# M4L2 register map
File version: 0.1
Registers are 32-bit, read-write, reset 0x0 unless marked. A register's access mark holds for its fields unless they carry their own. Offsets are from the block's base; [hi:lo] are bit positions; {n}, {i} and the like mark numbered series.

## PH — Port H
Base 0x40080700
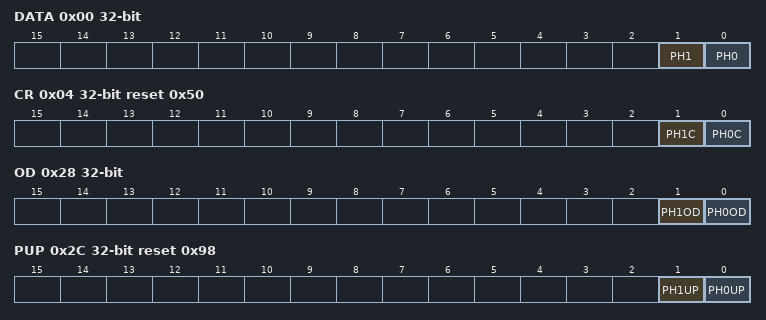
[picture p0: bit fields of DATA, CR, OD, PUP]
0x00 DATA — Port H Data Register
  [1] PH1, [0] PH0
0x04 CR reset 0x50 — Port H Output Control Register
  [1] PH1C, [0] PH0C
0x28 OD — Port H Open Drain Control Register
  [1] PH1OD, [0] PH0OD
0x2C PUP reset 0x98 — Port H Pull-up Control Register
  [1] PH1UP, [0] PH0UP
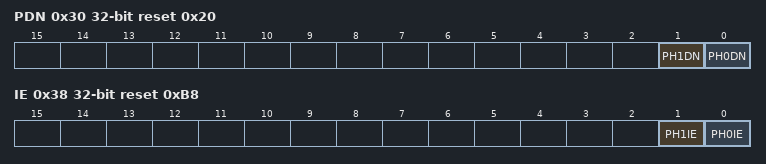
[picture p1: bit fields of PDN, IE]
0x30 PDN reset 0x20 — Port H Pull-down Control Register
  [1] PH1DN, [0] PH0DN
0x38 IE reset 0xB8 — Port H Input Control Register
  [1] PH1IE, [0] PH0IE

## PJ — Port J
Base 0x40080800
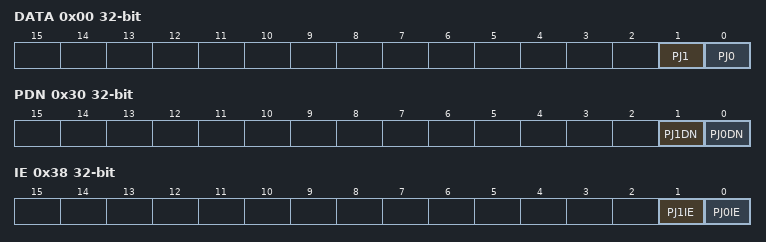
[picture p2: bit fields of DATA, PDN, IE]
0x00 DATA — Port J Data Register
  [1] PJ1, [0] PJ0
0x30 PDN — Port J Pull-down Control Register
  [1] PJ1DN, [0] PJ0DN
0x38 IE — Port J Input Control Register
  [1] PJ1IE, [0] PJ0IE

## PK — Port K
Base 0x40080900
0x00 DATA — Port K Data Register
  [0] PK0
0x04 CR — Port K Output Control Register
  [0] PK0C
0x28 OD — Port K Open Drain Control Register
  [0] PK0OD
0x2C PUP — Port K Pull-up Control Register
  [0] PK0UP
0x30 PDN reset 0x8 — Port K Pull-up Control Register
  [0] PK0DN
0x38 IE — Port K Input Control Register
  [0] PK0IE

## TRM — Internal High-speed Oscillation Adjustment
Base 0x40083100
0x00 OSCPRO — TRM Protection Register
  [7:0] PROTECT
0x04 OSCEN — TRM Enable Register
  [0] TRIMEN
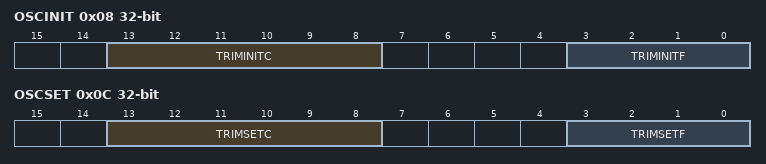
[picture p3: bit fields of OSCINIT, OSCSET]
0x08 OSCINIT ro (reset mask 0xFFFFC0F0) — TRM Initial Trimming Level Monitor Register
  [13:8] TRIMINITC, [3:0] TRIMINITF
0x0C OSCSET — TRM Trimming Level Setting Register
  [13:8] TRIMSETC, [3:0] TRIMSETF

## OFD — Oscillation Frequency Detector (OFD)
Base 0x40084000
0x00 CR1 reset 0x6 — OFD Control Register 1
  [7:0] OFDWEN
0x04 CR2 — OFD Control Register 2
  [7:0] OFDEN
0x08 MN0 — OFD Lower Detection Frequency Setting Register0
  [11:0] OFDMN0
0x0C MN1 — OFD Lower Detection Frequency Setting Register1
  [11:0] OFDMN1
0x10 MX0 — OFD Higher Detection Frequency Setting Register0
  [11:0] OFDMX0
0x14 MX1 — OFD Higher Detection Frequency Setting Register1
  [11:0] OFDMX1
0x18 RST reset 0x1 — OFD Reset Enable Control Register
  [0] OFDRSTEN
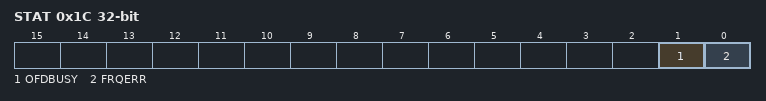
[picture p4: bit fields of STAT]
0x1C STAT ro — OFD Status Register
  [1] OFDBUSY, [0] FRQERR
0x20 MON reset 0x1 — OFD External high frequency oscillaion clock monitor register
  [0] OFDMON

## PMD
Base 0x40089000
0x00 MDEN — PMD Enable Register
  [0] PWMEN
0x04 PORTMD — PMD Port Output Mode Register
  [1:0] PORTMD
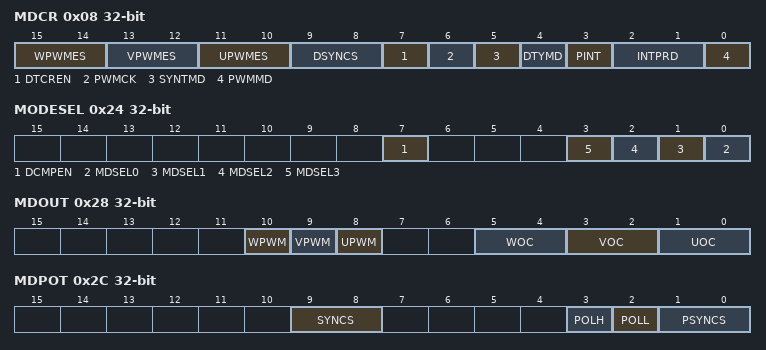
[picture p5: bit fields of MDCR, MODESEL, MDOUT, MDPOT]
0x08 MDCR — PMD Control Register
  [15:14] WPWMES, [13:12] VPWMES, [11:10] UPWMES, [9:8] DSYNCS, [7] DTCREN, [6] PWMCK, [5] SYNTMD, [4] DTYMD, [3] PINT, [2:1] INTPRD, [0] PWMMD
0x0C CNTSTA ro — PMD PWM Counter Status Register
  [0] UPDWN
0x10 MDCNT ro — PMD PWM Counter Register
  [15:0] MDCNT
0x14 MDPRD — PMD PWM Period Register
  [15:0] MDPRD
0x18 CMPU — PMD PWM Compare U Register
  [15:0] CMPU
0x1C CMPV — PMD PWM Compare V Register
  [15:0] CMPV
0x20 CMPW — PMD PWM Compare W Register
  [15:0] CMPW
0x24 MODESEL — PMD Mode Selection Register
  [7] DCMPEN, [n] MDSEL{n} (n=0..3)
0x28 MDOUT — PMD Conduction Control Register
  [10] WPWM, [9] VPWM, [8] UPWM, [5:4] WOC, [3:2] VOC, [1:0] UOC
0x2C MDPOT — PMD Output Setting Register
  [9:8] SYNCS, [3] POLH, [2] POLL, [1:0] PSYNCS
0x30 EMGREL wo — PMD EMG Release Register
  [7:0] EMGREL
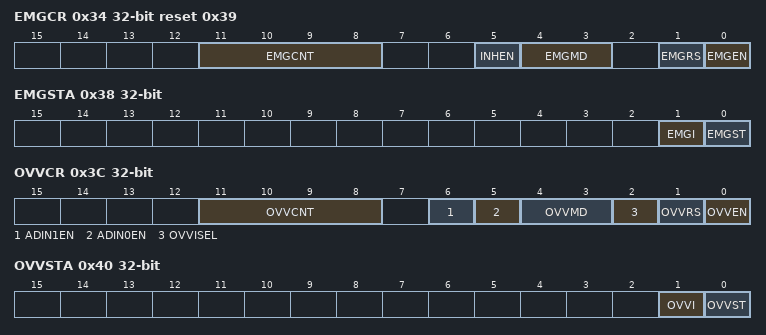
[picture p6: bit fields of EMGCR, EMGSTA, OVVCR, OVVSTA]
0x34 EMGCR reset 0x39 — PMD EMG Control Register
  [11:8] EMGCNT, [5] INHEN, [4:3] EMGMD, [1] EMGRS wo, [0] EMGEN
0x38 EMGSTA ro (reset mask 0xFFFFFFFD) — PMD EMG Status Register
  [1] EMGI, [0] EMGST
0x3C OVVCR — PMD OVV Control Register
  [11:8] OVVCNT, [6] ADIN1EN, [5] ADIN0EN, [4:3] OVVMD, [2] OVVISEL, [1] OVVRS, [0] OVVEN
0x40 OVVSTA ro (reset mask 0xFFFFFFFD) — PMD OVV Status Register
  [1] OVVI, [0] OVVST
0x44 DTR — PMD Dead Time Register
  [7:0] DTR
{0x48+4i} TRGCMP{i} (i=0..3) — PMD Trigger Compare Register {i}
  [15:0] TRGCMP{i}
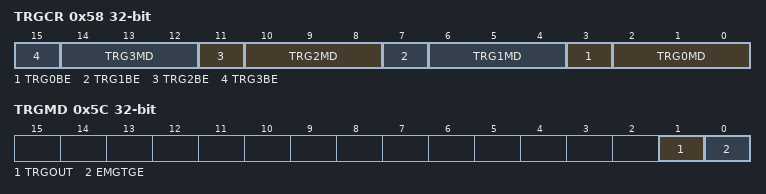
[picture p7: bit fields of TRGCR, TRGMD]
0x58 TRGCR — PMD Trigger Control Register
  [4n+3] TRG{n}BE (n=0..3), [4n+2:4n] TRG{n}MD (n=0..3)
0x5C TRGMD — PMD Trigger Output Mode Setting Register
  [1] TRGOUT, [0] EMGTGE
0x60 TRGSEL — PMD Trigger Output Select Register
  [2:0] TRGSEL
0x64 TRGSYNCR — PMD Trigger Update Timing Setting Register
  [1:0] TSYNCS

## EN — Advanced Encoder Input (A-ENC32)
Base 0x4008A000
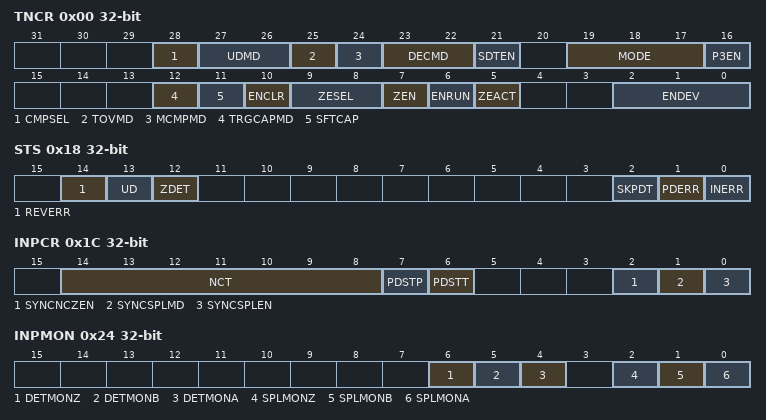
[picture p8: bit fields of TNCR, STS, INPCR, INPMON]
0x00 TNCR — ENC Control Register
  [28] CMPSEL, [27:26] UDMD, [25] TOVMD, [24] MCMPMD, [23:22] DECMD, [21] SDTEN, [19:17] MODE, [16] P3EN, [12] TRGCAPMD, [11] SFTCAP wo, [10] ENCLR wo, [9:8] ZESEL, [7] ZEN, [6] ENRUN, [5] ZEACT, [2:0] ENDEV
0x04 RELOAD — ENC Reload Compare Register
0x08 INT — ENC INT Compare Register
0x0C CNT ro — ENC Counter_Capture Register
0x10 MCMP — ENC MCMP Compare Register
0x14 RATE — ENC Phase Count Rate Register
  [15:0] RATE
0x18 STS ro — ENC Status Register
  [14] REVERR, [13] UD, [12] ZDET, [2] SKPDT, [1] PDERR, [0] INERR
0x1C INPCR — ENC Input Process Cntrol Register
  [14:8] NCT, [7] PDSTP wo, [6] PDSTT wo, [2] SYNCNCZEN, [1] SYNCSPLMD, [0] SYNCSPLEN
0x20 SMPDLY — ENC Sample Delay Register
  [7:0] SMPDLY
0x24 INPMON ro — ENC Input Moniter Register
  [6] DETMONZ, [5] DETMONB, [4] DETMONA, [2] SPLMONZ, [1] SPLMONB, [0] SPLMONA
0x28 CLKCR — ENC Sample Clock Control Register
  [1:0] SPLCKS
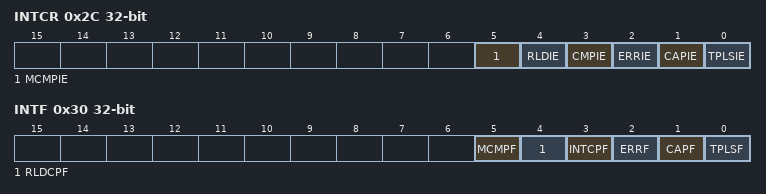
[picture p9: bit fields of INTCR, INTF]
0x2C INTCR — ENC Interrupt Reqyest Control Register
  [5] MCMPIE, [4] RLDIE, [3] CMPIE, [2] ERRIE, [1] CAPIE, [0] TPLSIE
0x30 INTF ro — ENC Interrupt Event Flag Register
  [5] MCMPF, [4] RLDCPF, [3] INTCPF, [2] ERRF, [1] CAPF, [0] TPLSF

## FC
Base 0x5DFF0000
0x10 SBMR reset 0x1 — Flash Security Bit Mask Register
  [0] SMB
0x14 SSR ro (reset mask 0xFFFFFFFE) — Flash Security Status Register
  [0] SEC
0x18 KCR wo — Flash Key Code Register
  [31:0] KEYCODE
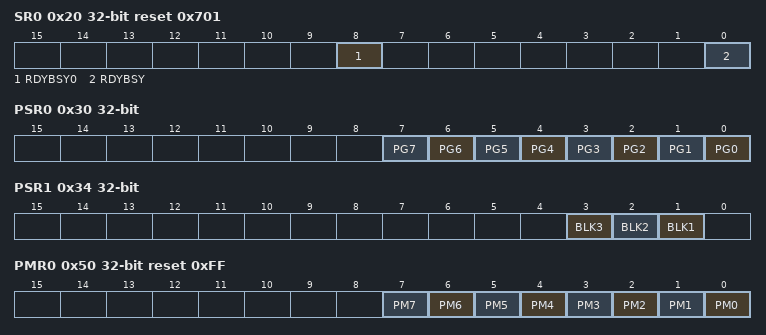
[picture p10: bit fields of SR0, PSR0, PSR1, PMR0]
0x20 SR0 ro reset 0x701 — Flash Status Register 0
  [8] RDYBSY0, [0] RDYBSY
0x30 PSR0 ro (reset mask 0xFFFFFF00) — Flash Protect Status Register 0
  [n] PG{n} (n=0..7)
0x34 PSR1 ro (reset mask 0x1) — Flash Protect Status Register 1
  [3] BLK3, [2] BLK2, [1] BLK1
0x50 PMR0 reset 0xFF — Flash Protect Mask Register 0
  [n] PM{n} (n=0..7)
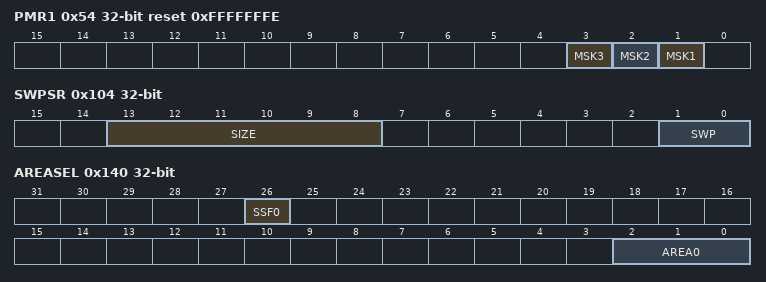
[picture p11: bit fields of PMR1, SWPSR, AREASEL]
0x54 PMR1 reset 0xFFFFFFFE — Flash Protect Mask Register 1
  [3] MSK3, [2] MSK2, [1] MSK1
0x100 SR1 ro — Flash Status Register 1
  [24] WEABORT
0x104 SWPSR ro — Flash Memory SWP Status Register
  [13:8] SIZE, [1:0] SWP
0x140 AREASEL — Flash Area Selection Register
  [26] SSF0 ro, [2:0] AREA0
0x148 CR — Flash Control Register
  [2:0] WEABORT
0x14C STSCLR — Flash Status Clear Register
  [2:0] WEABORT
0x150 BNKCR — Flash Bank Change Register
  [2:0] BANK0
0x158 BUFDISCLR — Flash Buffer Disable and Clear Register
  [2:0] BUFDISCLR
